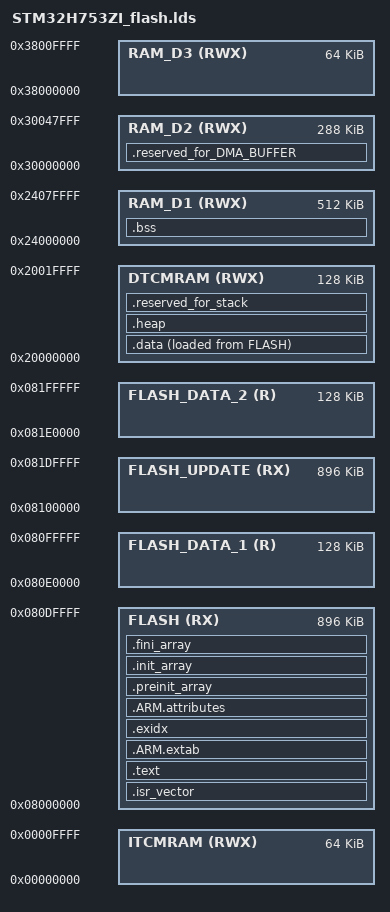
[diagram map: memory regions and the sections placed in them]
/* Generated by LinkerScriptGenerator [http://visualgdb.com/tools/LinkerScriptGenerator]
 * Target: STM32H753ZI
 * The file is provided under the BSD license.
 */

ENTRY(Reset_Handler)

MEMORY
{
    FLASH (RX)        : ORIGIN = 0x08000000, LENGTH = 1M - 128k
    FLASH_DATA_1 (R)  : ORIGIN = 0x080E0000, LENGTH = 128K
    FLASH_UPDATE (RX) : ORIGIN = 0x08100000, LENGTH = 1M - 128k    
    FLASH_DATA_2 (R)  : ORIGIN = 0x081E0000, LENGTH = 128K
    DTCMRAM (RWX)     : ORIGIN = 0x20000000, LENGTH = 128K
    RAM_D1 (RWX)      : ORIGIN = 0x24000000, LENGTH = 512K    						                                
    RAM_D2 (RWX)      : ORIGIN = 0x30000000, LENGTH = 288K
    RAM_D3 (RWX)      : ORIGIN = 0x38000000, LENGTH = 64K
    ITCMRAM (RWX)     : ORIGIN = 0x00000000, LENGTH = 64K                                 
}

_estack = ORIGIN(RAM_D3) + LENGTH(RAM_D3);

_FLASH_DATA_1      = ORIGIN(FLASH_DATA_1);
_FLASH_DATA_1_SIZE = LENGTH(FLASH_DATA_1);

_FLASH_DATA_2      = ORIGIN(FLASH_DATA_2);
_FLASH_DATA_2_SIZE = LENGTH(FLASH_DATA_2);

SECTIONS
{
    .isr_vector :
    {
        . = ALIGN(4);
        KEEP(*(.isr_vector))
        . = ALIGN(4);
    } > FLASH

    .text :
    {
        . = ALIGN(4);
        _stext = .;

        *(.text)
        *(.text*)
        *(.rodata)
        *(.rodata*)
        *(.glue_7)
        *(.glue_7t)
        KEEP(*(.init))
        KEEP(*(.fini))
        . = ALIGN(4);
        _etext = .;

    } > FLASH

    .ARM.extab :
    {
        . = ALIGN(4);
        *(.ARM.extab)
        *(.gnu.linkonce.armextab.*)
        . = ALIGN(4);
    } > FLASH

    .exidx :
    {
        . = ALIGN(4);
        PROVIDE(__exidx_start = .);
        *(.ARM.exidx*)
        . = ALIGN(4);
        PROVIDE(__exidx_end = .);
    } > FLASH

    .ARM.attributes :
    {
        *(.ARM.attributes)
    } > FLASH

    .preinit_array :
    {
        PROVIDE(__preinit_array_start = .);
        KEEP(*(.preinit_array*))
        PROVIDE(__preinit_array_end = .);
    } > FLASH

    .init_array :
    {
        PROVIDE(__init_array_start = .);
        KEEP(*(SORT(.init_array.*)))
        KEEP(*(.init_array*))
        PROVIDE(__init_array_end = .);
    } > FLASH

    .fini_array :
    {
        PROVIDE(__fini_array_start = .);
        KEEP(*(.fini_array*))
        KEEP(*(SORT(.fini_array.*)))
        PROVIDE(__fini_array_end = .);
    } > FLASH

    .data :
    {
        . = ALIGN(4);
        _sdata = .;

        PROVIDE(__data_start__ = _sdata);
        *(.data)
        *(.data*)
        . = ALIGN(4);
        _edata = .;

        PROVIDE(__data_end__ = _edata);
    } > DTCMRAM AT >FLASH

    _sidata = LOADADDR(.data);

    .bss :
    {
        . = ALIGN(4);
        _sbss = .;

        PROVIDE(__bss_start__ = _sbss);
        *(.bss)
        *(.bss*)
        *(COMMON)
        . = ALIGN(4);
        _ebss = .;

        PROVIDE(__bss_end__ = _ebss);
    } > RAM_D1

    PROVIDE(end = .);

    .heap (NOLOAD) :
    {
        . = ALIGN(4);
        PROVIDE(__heap_start__ = .);
        KEEP(*(.heap))
        . = ALIGN(4);
        PROVIDE(__heap_end__ = .);
    } > DTCMRAM

    .reserved_for_stack (NOLOAD) :
    {
        . = ALIGN(4);
        PROVIDE(__reserved_for_stack_start__ = .);
        KEEP(*(.reserved_for_stack))
        . = ALIGN(4);
        PROVIDE(__reserved_for_stack_end__ = .);
    } > DTCMRAM

    .reserved_for_DMA_BUFFER (NOLOAD) :
    {
        . = ALIGN(32);
        PROVIDE(__reserved_for_DMA_BUFFER_start__ = .);
        KEEP(*(.reserved_for_DMA_BUFFER))
        . = ALIGN(32);
        PROVIDE(__reserved_for_DMA_BUFFER_end__ = .);
    } > RAM_D2
    
  /* Remove information from the standard libraries */
  /DISCARD/ :
  {
    libc.a ( * )
    libm.a ( * )
    libgcc.a ( * )
  }

  .ARM.attributes 0 : { *(.ARM.attributes) }     
}

